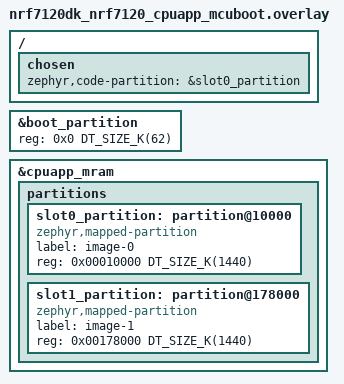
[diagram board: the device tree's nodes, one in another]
/*
 * Copyright (c) 2026 Nordic Semiconductor ASA
 *
 * SPDX-License-Identifier: LicenseRef-Nordic-5-Clause
 */

/*
 * Single-stage (MCUboot -> application) layout for nRF7120, no Partition
 * Manager. MCUboot is the first (and only) bootloader and protects itself:
 * it locks its own slot read/write/execute-disabled before jumping to the app.
 *
 *   boot_partition   0x000000   62K     MCUboot (self-locked)
 *   slot0_partition  0x010000   1440K   application image-0 (MCUboot primary)
 *   slot1_partition  0x178000   1440K   application image-1 (MCUboot secondary)
 *
 * MCUboot is sized at 62K because a single MRAMC region protects at most 31 KiB;
 * the self-RWX lock chains regions no.4 and no.5 to cover the whole 62K slot
 * (see NCS_MCUBOOT_DISABLE_SELF_RWX in sdk-mcuboot). This mirrors the nRF54L
 * reference (boards/nrf54l15dk_nrf54l15_cpuapp_mcuboot.overlay) but, unlike it,
 * does NOT '/delete-node/' the whole partitions node: the nRF7120 board defines
 * Wi-Fi ROM-patch partitions (wifi_lmac_patch_partition / wifi_umac_patch_
 * partition, at/above 0x2e0000) referenced by phandle, so removing the node
 * would leave dangling phandles and break the build. MRAM (not RRAM) and Wi-Fi
 * are nRF7120-specific divergences from the nRF54L reference.
 */

/* Resize MCUboot in place; boot_partition sits at 0x0 on the nRF7120 board. */
&boot_partition {
	reg = <0x0 DT_SIZE_K(62)>;
};

/delete-node/ &slot0_partition;
/delete-node/ &slot1_partition;

&cpuapp_mram {
	partitions {
		slot0_partition: partition@10000 {
			compatible = "zephyr,mapped-partition";
			label = "image-0";
			reg = <0x00010000 DT_SIZE_K(1440)>;
		};

		slot1_partition: partition@178000 {
			compatible = "zephyr,mapped-partition";
			label = "image-1";
			reg = <0x00178000 DT_SIZE_K(1440)>;
		};
	};
};

/ {
	chosen {
		zephyr,code-partition = &slot0_partition;
	};
};
